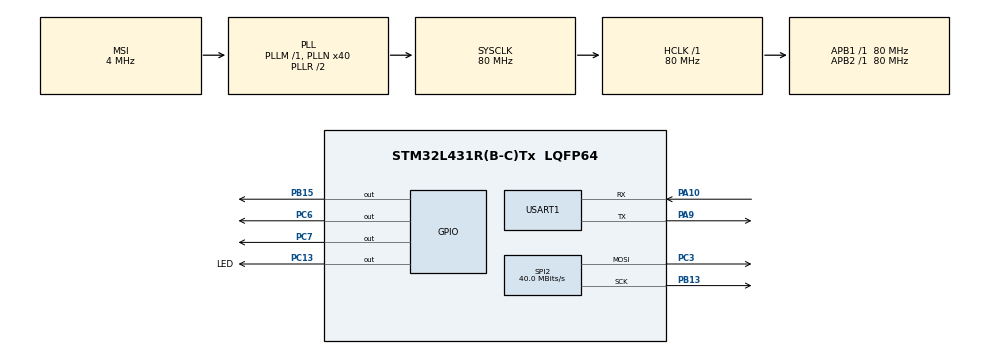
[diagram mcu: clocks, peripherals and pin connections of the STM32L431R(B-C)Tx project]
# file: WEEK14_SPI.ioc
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Mcu.Family=STM32L4
Mcu.Name=STM32L431R(B-C)Tx
Mcu.Package=LQFP64
NVIC.PriorityGroup=NVIC_PRIORITYGROUP_4
NVIC.SPI2_IRQn=true\:0\:0\:false\:false\:true\:true\:true\:true
NVIC.USART1_IRQn=true\:0\:0\:false\:false\:true\:true\:true\:true
PA10.Mode=Asynchronous
PA10.Signal=USART1_RX
PA13\ (JTMS-SWDIO).Mode=Serial_Wire
PA13\ (JTMS-SWDIO).Signal=SYS_JTMS-SWDIO
PA14\ (JTCK-SWCLK).Mode=Serial_Wire
PA14\ (JTCK-SWCLK).Signal=SYS_JTCK-SWCLK
PA9.Mode=Asynchronous
PA9.Signal=USART1_TX
PB13.Mode=TX_Only_Simplex_Unidirect_Master
PB13.Signal=SPI2_SCK
PB15.Signal=GPIO_Output
PC13.GPIO_Label=LED
PC13.Signal=GPIO_Output
PC3.Mode=TX_Only_Simplex_Unidirect_Master
PC3.Signal=SPI2_MOSI
PC6.Signal=GPIO_Output
PC7.Signal=GPIO_Output
ProjectManager.HeapSize=0x200
ProjectManager.StackSize=0x400
ProjectManager.TargetToolchain=MDK-ARM V5.32
RCC.AHBFreq_Value=80000000
RCC.APB1Freq_Value=80000000
RCC.APB1TimFreq_Value=80000000
RCC.APB2Freq_Value=80000000
RCC.APB2TimFreq_Value=80000000
RCC.CortexFreq_Value=80000000
RCC.HCLKFreq_Value=80000000
RCC.HSE_VALUE=8000000
RCC.HSI48_VALUE=48000000
RCC.HSI_VALUE=16000000
RCC.LSE_VALUE=32768
RCC.MSI_VALUE=4000000
RCC.PLLN=40
RCC.SYSCLKFreq_VALUE=80000000
RCC.SYSCLKSource=RCC_SYSCLKSOURCE_PLLCLK
RCC.VCOOutputFreq_Value=160000000
SPI2.CLKPhase=SPI_PHASE_2EDGE
SPI2.CLKPolarity=SPI_POLARITY_HIGH
SPI2.CalculateBaudRate=40.0 MBits/s
SPI2.DataSize=SPI_DATASIZE_8BIT
SPI2.Direction=SPI_DIRECTION_2LINES
SPI2.Mode=SPI_MODE_MASTER
SPI2.VirtualType=VM_MASTER
USART1.VirtualMode-Asynchronous=VM_ASYNC
board=custom

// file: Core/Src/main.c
/* USER CODE BEGIN Header */
/**
  ******************************************************************************
  * @file           : main.c
  * @brief          : Main program body
  ******************************************************************************
  * @attention
  *
  * Copyright (c) 2022 STMicroelectronics.
  * All rights reserved.
  *
  * This software is licensed under terms that can be found in the LICENSE file
  * in the root directory of this software component.
  * If no LICENSE file comes with this software, it is provided AS-IS.
  *
  ******************************************************************************
  */
/* USER CODE END Header */
#include "main.h"
#include "spi.h"
#include "usart.h"
#include "gpio.h"

/* USER CODE BEGIN Includes */
#include "stdio.h"
#include "lcd.h"
/* USER CODE END Includes */

void SystemClock_Config(void);

int main(void)
{

  /* MCU Configuration--------------------------------------------------------*/

  /* Reset of all peripherals, Initializes the Flash interface and the Systick. */
  HAL_Init();

  /* Configure the system clock */
  SystemClock_Config();

  /* Initialize all configured peripherals */
  MX_GPIO_Init();
  MX_SPI2_Init();
  MX_USART1_UART_Init();
  /* USER CODE BEGIN 2 */
	printf("Welcom to STM32L4!");
	LCD_Init();
  /* USER CODE END 2 */

  /* Infinite loop */
  while (1)
  {
		LCD_Clear(BLACK);
		LCD_ShowString(5, 10, 240, 32, 32, "BearPi LCDTest");
		LCD_ShowString(10, 50, 240, 16, 16, "Welcome to IoT CluB!");
		LCD_ShowString(10, 50 + 24, 240, 24, 24, "to IoT Club!");
		LCD_ShowString(10, 50 + 24 + 32, 240, 32, 32, "IoT CluB!");
		PutChinese_strings(10, 150, "֣����������", 0);
		printf("֣���桢������\r\n");
		HAL_GPIO_WritePin(LED_GPIO_Port, LED_Pin, GPIO_PIN_SET);
		HAL_Delay(1000);
		LCD_Clear(BLUE);
		LCD_Draw_Circle(120, 120, 100);
		LCD_Draw_Circle(120, 120, 80);
		LCD_Draw_Circle(120, 120, 60);
		LCD_Draw_Circle(120, 120, 40);
		LCD_Draw_Circle(120, 120, 20);
		LCD_Draw_Circle(120, 120, 1);
		HAL_GPIO_WritePin(LED_GPIO_Port, LED_Pin, GPIO_PIN_RESET);
		HAL_Delay(1000);
  }
}

void SystemClock_Config(void)
{
  RCC_OscInitTypeDef RCC_OscInitStruct = {0};
  RCC_ClkInitTypeDef RCC_ClkInitStruct = {0};

  /** Configure the main internal regulator output voltage
  */
  if (HAL_PWREx_ControlVoltageScaling(PWR_REGULATOR_VOLTAGE_SCALE1) != HAL_OK)
  {
    Error_Handler();
  }

  /** Initializes the RCC Oscillators according to the specified parameters
  * in the RCC_OscInitTypeDef structure.
  */
  RCC_OscInitStruct.OscillatorType = RCC_OSCILLATORTYPE_MSI;
  RCC_OscInitStruct.MSIState = RCC_MSI_ON;
  RCC_OscInitStruct.MSICalibrationValue = 0;
  RCC_OscInitStruct.MSIClockRange = RCC_MSIRANGE_6;
  RCC_OscInitStruct.PLL.PLLState = RCC_PLL_ON;
  RCC_OscInitStruct.PLL.PLLSource = RCC_PLLSOURCE_MSI;
  RCC_OscInitStruct.PLL.PLLM = 1;
  RCC_OscInitStruct.PLL.PLLN = 40;
  RCC_OscInitStruct.PLL.PLLP = RCC_PLLP_DIV7;
  RCC_OscInitStruct.PLL.PLLQ = RCC_PLLQ_DIV2;
  RCC_OscInitStruct.PLL.PLLR = RCC_PLLR_DIV2;
  if (HAL_RCC_OscConfig(&RCC_OscInitStruct) != HAL_OK)
  {
    Error_Handler();
  }

  /** Initializes the CPU, AHB and APB buses clocks
  */
  RCC_ClkInitStruct.ClockType = RCC_CLOCKTYPE_HCLK|RCC_CLOCKTYPE_SYSCLK
                              |RCC_CLOCKTYPE_PCLK1|RCC_CLOCKTYPE_PCLK2;
  RCC_ClkInitStruct.SYSCLKSource = RCC_SYSCLKSOURCE_PLLCLK;
  RCC_ClkInitStruct.AHBCLKDivider = RCC_SYSCLK_DIV1;
  RCC_ClkInitStruct.APB1CLKDivider = RCC_HCLK_DIV1;
  RCC_ClkInitStruct.APB2CLKDivider = RCC_HCLK_DIV1;

  if (HAL_RCC_ClockConfig(&RCC_ClkInitStruct, FLASH_LATENCY_4) != HAL_OK)
  {
    Error_Handler();
  }
}

void Error_Handler(void)
{
  __disable_irq();
  while (1)
  {
  }
}
